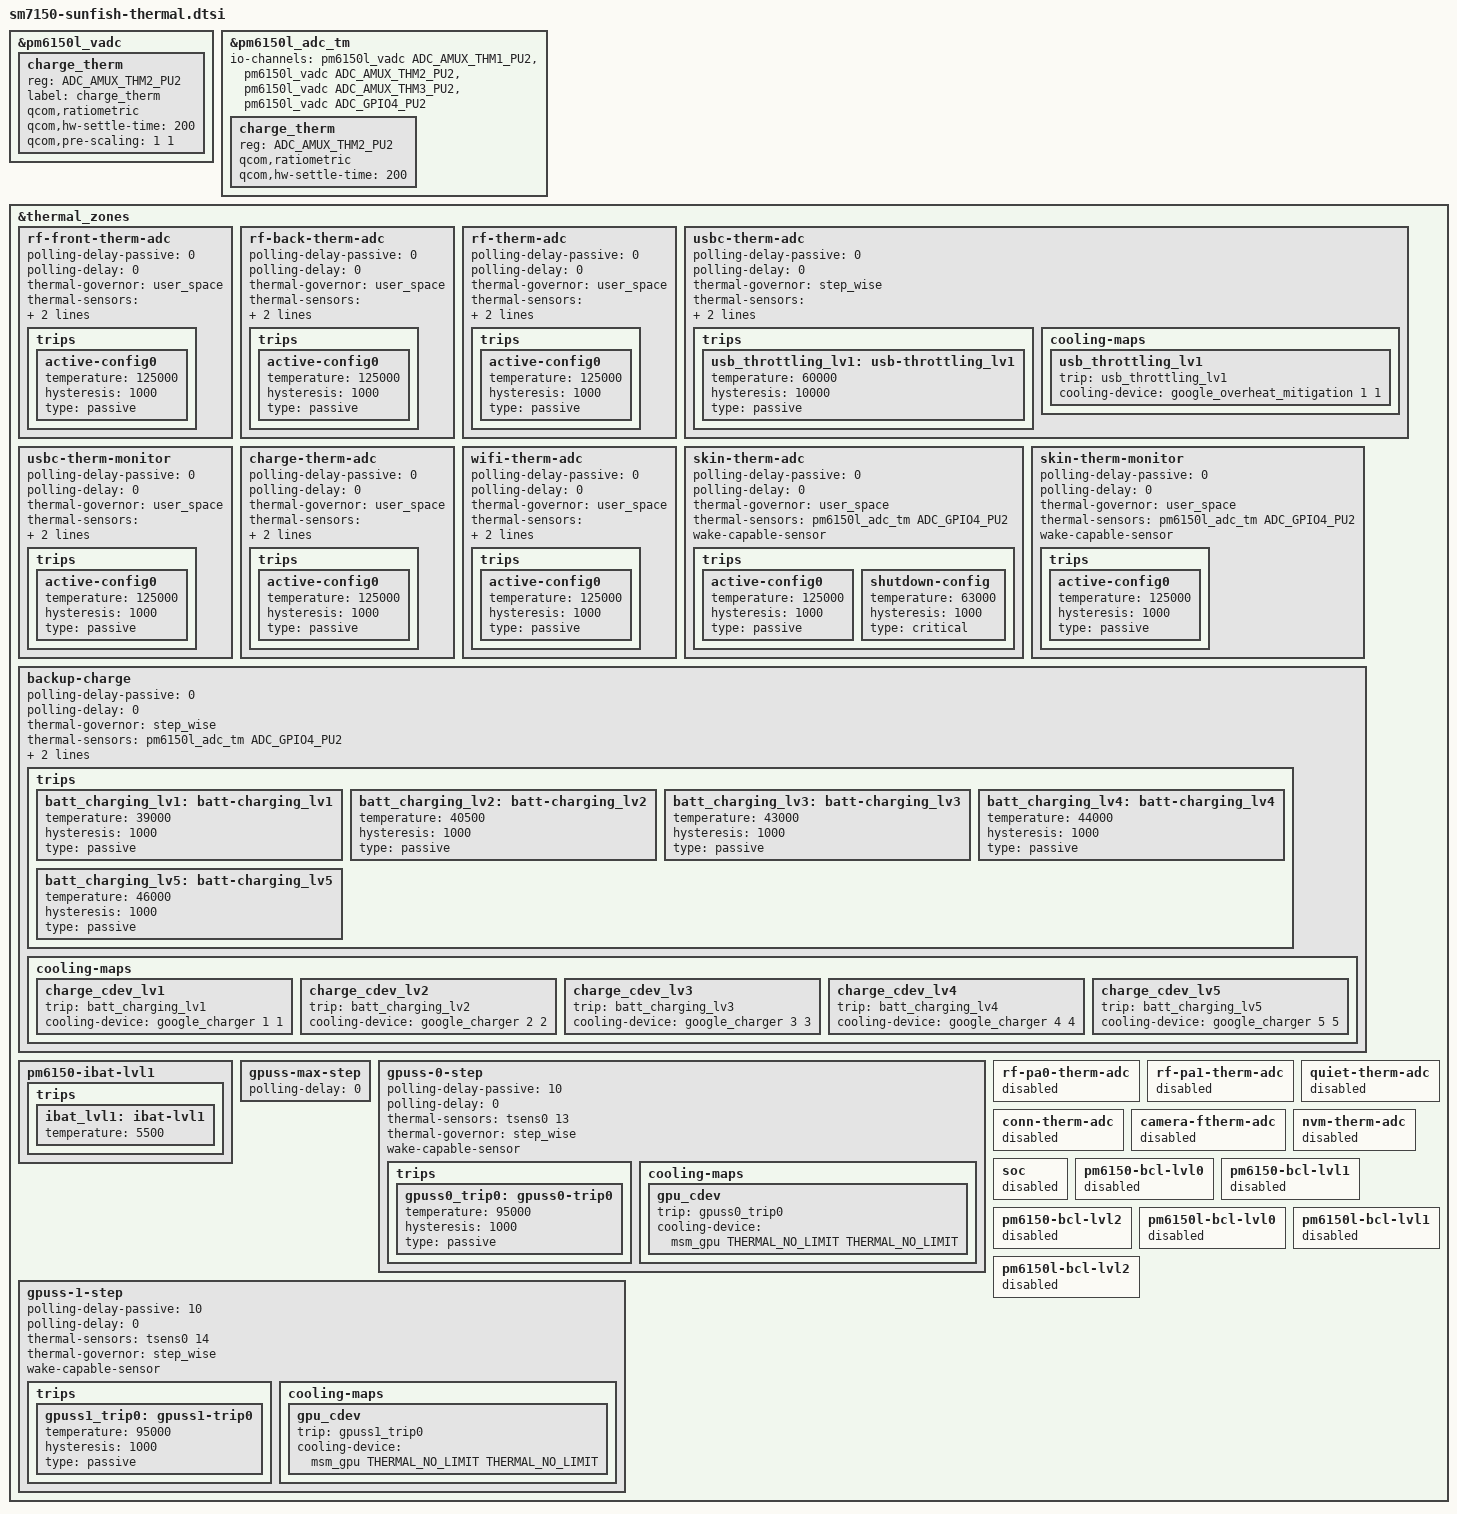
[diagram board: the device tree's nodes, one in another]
/* Copyright (c) 2018-2019, The Linux Foundation. All rights reserved.
 *
 * This program is free software; you can redistribute it and/or modify
 * it under the terms of the GNU General Public License version 2 and
 * only version 2 as published by the Free Software Foundation.
 *
 * This program is distributed in the hope that it will be useful,
 * but WITHOUT ANY WARRANTY; without even the implied warranty of
 * MERCHANTABILITY or FITNESS FOR A PARTICULAR PURPOSE.  See the
 * GNU General Public License for more details.
 */

&pm6150l_vadc {
	charge_therm {
		reg = <ADC_AMUX_THM2_PU2>;
		label = "charge_therm";
		qcom,ratiometric;
		qcom,hw-settle-time = <200>;
		qcom,pre-scaling = <1 1>;
	};
};

&pm6150l_adc_tm {
	io-channels = <&pm6150l_vadc ADC_AMUX_THM1_PU2>,
			<&pm6150l_vadc ADC_AMUX_THM2_PU2>,
			<&pm6150l_vadc ADC_AMUX_THM3_PU2>,
			<&pm6150l_vadc ADC_GPIO4_PU2>;

	charge_therm {
		reg = <ADC_AMUX_THM2_PU2>;
		qcom,ratiometric;
		qcom,hw-settle-time = <200>;
	};
};

/*
 * Vadc: pm6150_vadc
 * Rename rf-pa0-therm-adc to rf-front-therm-adc, label: rf_pa0_therm
 * Rename rf-pa1-therm-adc to rf-back-therm-adc, label: rf_pa1_therm
 * Rename quiet-therm-adc to rf-therm-adc, label: quiet_therm
 * Vadc: pm6150l_vadc
 * Rename conn-therm-adc to usbc-therm-adc, label: conn_therm
 * Rename camera-ftherm-adc to wifi-therm-adc, label: camera_ftherm
 * Rename nvm-therm-adc to skin-therm-adc, label: nvm_therm
 * Add charge-therm-adc, label: charge_therm
 */
&thermal_zones {
	rf-front-therm-adc {
		polling-delay-passive = <0>;
		polling-delay = <0>;
		thermal-governor = "user_space";
		thermal-sensors = <&pm6150_adc_tm ADC_AMUX_THM2_PU2>;
		wake-capable-sensor;
		trips {
			active-config0 {
				temperature = <125000>;
				hysteresis = <1000>;
				type = "passive";
			};
		};
	};

	rf-back-therm-adc {
		polling-delay-passive = <0>;
		polling-delay = <0>;
		thermal-governor = "user_space";
		thermal-sensors = <&pm6150_adc_tm ADC_AMUX_THM3_PU2>;
		wake-capable-sensor;
		trips {
			active-config0 {
				temperature = <125000>;
				hysteresis = <1000>;
				type = "passive";
			};
		};
	};

	rf-therm-adc {
		polling-delay-passive = <0>;
		polling-delay = <0>;
		thermal-governor = "user_space";
		thermal-sensors = <&pm6150_adc_tm ADC_AMUX_THM4_PU2>;
		wake-capable-sensor;
		trips {
			active-config0 {
				temperature = <125000>;
				hysteresis = <1000>;
				type = "passive";
			};
		};
	};

	usbc-therm-adc {
		polling-delay-passive = <0>;
		polling-delay = <0>;
		thermal-governor = "step_wise";
		thermal-sensors = <&pm6150l_adc_tm ADC_AMUX_THM1_PU2>;
		wake-capable-sensor;
		trips {
			usb_throttling_lv1: usb-throttling_lv1 {
				temperature = <60000>;
				hysteresis = <10000>;
				type = "passive";
			};
		};
		cooling-maps {
			usb_throttling_lv1 {
				trip = <&usb_throttling_lv1>;
				cooling-device =
					<&google_overheat_mitigation 1 1>;
			};
		};
	};

	usbc-therm-monitor {
		polling-delay-passive = <0>;
		polling-delay = <0>;
		thermal-governor = "user_space";
		thermal-sensors = <&pm6150l_adc_tm ADC_AMUX_THM1_PU2>;
		wake-capable-sensor;
		trips {
			active-config0 {
				temperature = <125000>;
				hysteresis = <1000>;
				type = "passive";
			};
		};
	};

	charge-therm-adc {
		polling-delay-passive = <0>;
		polling-delay = <0>;
		thermal-governor = "user_space";
		thermal-sensors = <&pm6150l_adc_tm ADC_AMUX_THM2_PU2>;
		wake-capable-sensor;
		trips {
			active-config0 {
				temperature = <125000>;
				hysteresis = <1000>;
				type = "passive";
			};
		};
	};

	wifi-therm-adc {
		polling-delay-passive = <0>;
		polling-delay = <0>;
		thermal-governor = "user_space";
		thermal-sensors = <&pm6150l_adc_tm ADC_AMUX_THM3_PU2>;
		wake-capable-sensor;
		trips {
			active-config0 {
				temperature = <125000>;
				hysteresis = <1000>;
				type = "passive";
			};
		};
	};

	skin-therm-adc {
		polling-delay-passive = <0>;
		polling-delay = <0>;
		thermal-governor = "user_space";
		thermal-sensors = <&pm6150l_adc_tm ADC_GPIO4_PU2>;
		wake-capable-sensor;
		trips {
			active-config0 {
				temperature = <125000>;
				hysteresis = <1000>;
				type = "passive";
			};

			shutdown-config {
				temperature = <63000>;
				hysteresis = <1000>;
				type = "critical";
			};
		};
	};

	skin-therm-monitor {
		polling-delay-passive = <0>;
		polling-delay = <0>;
		thermal-governor = "user_space";
		thermal-sensors = <&pm6150l_adc_tm ADC_GPIO4_PU2>;
		wake-capable-sensor;
		trips {
			active-config0 {
				temperature = <125000>;
				hysteresis = <1000>;
				type = "passive";
			};
		};
	};

	backup-charge {
		polling-delay-passive = <0>;
		polling-delay = <0>;
		thermal-governor = "step_wise";
		thermal-sensors = <&pm6150l_adc_tm ADC_GPIO4_PU2>;
		wake-capable-sensor;
		disable-thermal-zone;
		trips {
			batt_charging_lv1: batt-charging_lv1 {
				temperature = <39000>;
				hysteresis = <1000>;
				type = "passive";
			};
			batt_charging_lv2: batt-charging_lv2 {
				temperature = <40500>;
				hysteresis = <1000>;
				type = "passive";
			};
			batt_charging_lv3: batt-charging_lv3 {
				temperature = <43000>;
				hysteresis = <1000>;
				type = "passive";
			};
			batt_charging_lv4: batt-charging_lv4 {
				temperature = <44000>;
				hysteresis = <1000>;
				type = "passive";
			};
			batt_charging_lv5: batt-charging_lv5 {
				temperature = <46000>;
				hysteresis = <1000>;
				type = "passive";
			};
		};

		cooling-maps {
			charge_cdev_lv1 {
				trip = <&batt_charging_lv1>;
				cooling-device = <&google_charger 1 1>;
			};
			charge_cdev_lv2 {
				trip = <&batt_charging_lv2>;
				cooling-device = <&google_charger 2 2>;
			};
			charge_cdev_lv3 {
				trip = <&batt_charging_lv3>;
				cooling-device = <&google_charger 3 3>;
			};
			charge_cdev_lv4 {
				trip = <&batt_charging_lv4>;
				cooling-device = <&google_charger 4 4>;
			};
			charge_cdev_lv5 {
				trip = <&batt_charging_lv5>;
				cooling-device = <&google_charger 5 5>;
			};
		};
	};

	pm6150-ibat-lvl1 {
		trips {
			ibat_lvl1:ibat-lvl1 {
				temperature = <5500>;
			};
		};
	};

	gpuss-max-step {
		polling-delay = <0>;
	};

	gpuss-0-step {
		polling-delay-passive = <10>;
		polling-delay = <0>;
		thermal-sensors = <&tsens0 13>;
		thermal-governor = "step_wise";
		wake-capable-sensor;
		trips {
			gpuss0_trip0: gpuss0-trip0 {
				temperature = <95000>;
				hysteresis = <1000>;
				type = "passive";
			};
		};
		cooling-maps {
			gpu_cdev {
				trip = <&gpuss0_trip0>;
				cooling-device = <&msm_gpu THERMAL_NO_LIMIT
							THERMAL_NO_LIMIT>;
			};
		};
	};

	gpuss-1-step {
		polling-delay-passive = <10>;
		polling-delay = <0>;
		thermal-sensors = <&tsens0 14>;
		thermal-governor = "step_wise";
		wake-capable-sensor;
		trips {
			gpuss1_trip0: gpuss1-trip0 {
				temperature = <95000>;
				hysteresis = <1000>;
				type = "passive";
			};
		};
		cooling-maps {
			gpu_cdev {
				trip = <&gpuss1_trip0>;
				cooling-device = <&msm_gpu THERMAL_NO_LIMIT
							THERMAL_NO_LIMIT>;
			};
		};
	};

	/* Remove redundant QCT thermal zones */
	rf-pa0-therm-adc {
		status = "disabled";
	};

	rf-pa1-therm-adc {
		status = "disabled";
	};

	quiet-therm-adc {
		status = "disabled";
	};

	conn-therm-adc {
		status = "disabled";
	};

	camera-ftherm-adc {
		status = "disabled";
	};

	nvm-therm-adc {
		status = "disabled";
	};

	/* Disable QCT default BCL throttling */
	soc {
		status = "disabled";
	};

	pm6150-bcl-lvl0 {
		status = "disabled";
	};

	pm6150-bcl-lvl1	{
		status = "disabled";
	};

	pm6150-bcl-lvl2	{
		status = "disabled";
	};

	pm6150l-bcl-lvl0 {
		status = "disabled";
	};

	pm6150l-bcl-lvl1 {
		status = "disabled";
	};

	pm6150l-bcl-lvl2 {
		status = "disabled";
	};
};
